# STC32G144K246 register map
Vendor: STC; File version: 2.0
Registers are 8-bit, read-write, no defined reset value unless marked. A register's access mark holds for its fields unless they carry their own. Offsets are from the block's base; [hi:lo] are bit positions.

## PGA2 — 可编程增益放大器 / 运放 2
Base 0x007EF604
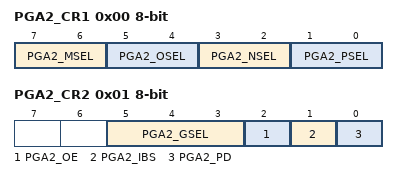
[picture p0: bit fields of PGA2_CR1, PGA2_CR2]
0x00 PGA2_CR1 — 运放2控制寄存器1
  [7:6] PGA2_MSEL — PGA2工作模式选择寄存器
    0=通用运放模式; 1=缓冲模式; 2=反相放大模式; 3=非反相放大模式
  [5:4] PGA2_OSEL — PGA2输出端口选择寄存器
    0=P4.2; 1=P0.0; 2=P7.4; 3=P6.2
  [3:2] PGA2_NSEL — PGA2负极端口选择寄存器
    0=P2.7; 1=P6.1; 2=P7.6; 3=DAC2O
  [1:0] PGA2_PSEL — PGA2正极端口选择寄存器
    0=P2.6; 1=P6.0; 2=P7.5; 3=P7.7
0x01 PGA2_CR2 — 运放2控制寄存器2
  [5:3] PGA2_GSEL — PGA2增益控制寄存器
    0=反相放大增益倍数：N/A；非反相放大增益倍数：N/A; 1=反相放大增益倍数：1；非反相放大增益倍数：2; 2=反相放大增益倍数：2；非反相放大增益倍数：3; 3=反相放大增益倍数：4；非反相放大增益倍数：5; 4=反相放大增益倍数：8；非反相放大增益倍数：9; 5=反相放大增益倍数：16；非反相放大增益倍数：17; 6=反相放大增益倍数：32；非反相放大增益倍数：33; 7=反相放大增益倍数：48；非反相放大增益倍数：49
  [2] PGA2_OE — PGA2 输出控制位
    0=禁止PGA2 输出; 1=允许PGA2 输出
  [1] PGA2_IBS — PGA2 偏压电流大小选择
    0=正常电流大小; 1=电流倍增
  [0] PGA2_PD — PGA2 电源控制
    0=禁止掉电（使能PGA2）; 1=使能掉电（关闭PGA2）

## Comparator3 — 比较器 3 配置与输出状态
Base 0x007EFB78
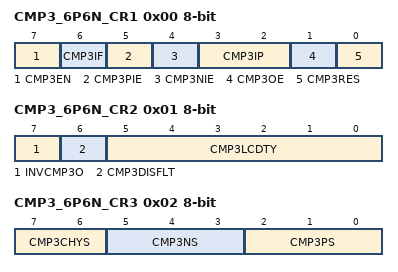
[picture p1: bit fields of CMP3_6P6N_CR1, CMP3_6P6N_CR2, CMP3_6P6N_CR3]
0x00 CMP3_6P6N_CR1 ro — 比较器3控制寄存器1
  [7] CMP3EN — 比较器模块使能位
    0=关闭比较功能; 1=使能比较功能
  [6] CMP3IF — 比较器3 中断标志位。当CMP3PIE 或CMP3NIE 被使能后，若产生相应的中断信号，硬件自 动将CMP3IF 置1，并向CPU 提出中断请求。此标志位必须用户软件向此位写0 清零。
  [5] CMP3PIE — 比较器3 上升沿中断使能位。
    0=禁止比较器3 上升沿中断。; 1=使能比较器3 上升沿中断。使能比较器3 的比较结果由0 变成1 时产生中断请求。
  [4] CMP3NIE — 比较器3 下降沿中断使能位。
    0=禁止比较器3 下降沿中断。; 1=使能比较器3 下降沿中断。使能比较器3 的比较结果由1 变成0 时产生中断请求。
  [3:2] CMP3IP — 比较器3 中断优先级设置。
    0=比较器3 中断为最低优先级。; 1=比较器3 中断为较低优先级。; 2=比较器3 中断为较高优先级。; 3=比较器3 中断为最高优先级。
  [1] CMP3OE — 比较器结果输出控制位
    0=禁止比较器结果输出; 1=使能比较器结果输出。
  [0] CMP3RES — 比较器的比较结果。此位为只读。
    0=表示CMP3+的电平低于CMP3-的电平; 1=表示CMP3+的电平高于CMP3-的电平
0x01 CMP3_6P6N_CR2 ro — 比较器3控制寄存器2
  [7] INVCMP3O — 比较器结果输出控制
    0=比较器结果正向输出。若CMP3RES 为0，则输出低电平，反之输出高电平。; 1=比较器结果反向输出。若CMP3RES 为0，则输出高电平，反之输出低电平。
  [6] CMP3DISFLT — 模拟滤波功能控制
    0=使能0.1us 模拟滤波功能; 1=关闭0.1us 模拟滤波功能，可略微提高比较器的比较速度。
  [5:0] CMP3LCDTY — 数字滤波功能控制 数字滤波功能即为数字信号去抖动功能。当比较结果发生上升沿或者下降沿变化时，比较器侦测变 化后的信号必须维持LCDTY 所设置的CPU 时钟数不发生变化，才认为数据变化是有效的；否 则将视同信号无变化。 注意：当使能数字滤波功能后，芯片内部实际的等待时钟需额外增加两个状态机切换时间，
0x02 CMP3_6P6N_CR3 ro — 比较器3控制寄存器3
  [7:6] CMP3CHYS — 比较器DC 迟滞输入选择
  [5:3] CMP3NS — 比较器负端输入选择
    0=P7.6; 1=P5.2; 2=OP4O; 3=1.19V; 4=DAC1O; 5=DAC2O
  [2:0] CMP3PS — 比较器正端输入选择
    0=P7.7; 1=P5.3; 2=OP3O; 3=ADC2IN; 4=DAC1O; 5=DAC2O
0x03 CMP3_6P6N_CR4 ro — 比较器3控制寄存器4
  [1:0] CMP3O_S — 比较器输出端口选择
    0=P2.4; 1=P4.5; 2=Value_2; 3=Value_3

## PGA3 — 可编程增益放大器 / 运放 3
Base 0x007EF608
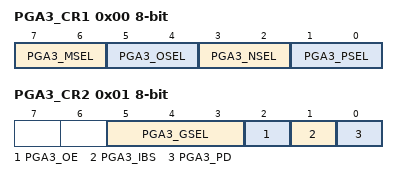
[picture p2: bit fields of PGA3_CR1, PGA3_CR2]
0x00 PGA3_CR1 — 运放3控制寄存器1
  [7:6] PGA3_MSEL — PGA3工作模式选择寄存器
    0=通用运放模式; 1=缓冲模式; 2=反相放大模式; 3=非反相放大模式
  [5:4] PGA3_OSEL — PGA3输出端口选择寄存器
    0=P3.2; 1=P2.1; 2=P7.4; 3=P5.0
  [3:2] PGA3_NSEL — PGA3负极端口选择寄存器
    0=P5.1; 1=P4.2; 2=P7.1; 3=DAC2O
  [1:0] PGA3_PSEL — PGA3正极端口选择寄存器
    0=P3.5; 1=P2.0; 2=P7.0; 3=DAC2O
0x01 PGA3_CR2 — 运放3控制寄存器2
  [5:3] PGA3_GSEL — PGA3增益控制寄存器
    0=反相放大增益倍数：N/A；非反相放大增益倍数：N/A; 1=反相放大增益倍数：1；非反相放大增益倍数：2; 2=反相放大增益倍数：2；非反相放大增益倍数：3; 3=反相放大增益倍数：4；非反相放大增益倍数：5; 4=反相放大增益倍数：8；非反相放大增益倍数：9; 5=反相放大增益倍数：16；非反相放大增益倍数：17; 6=反相放大增益倍数：32；非反相放大增益倍数：33; 7=反相放大增益倍数：48；非反相放大增益倍数：49
  [2] PGA3_OE — PGA3 输出控制位
    0=禁止PGA3 输出; 1=允许PGA3 输出
  [1] PGA3_IBS — PGA3 偏压电流大小选择
    0=正常电流大小; 1=电流倍增
  [0] PGA3_PD — PGA3 电源控制
    0=禁止掉电（使能PGA3）; 1=使能掉电（关闭PGA3）

## Comparator4 — 比较器 4 配置与输出状态
Base 0x007EFB7C
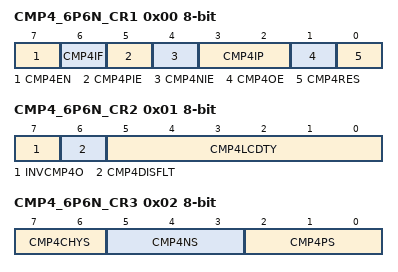
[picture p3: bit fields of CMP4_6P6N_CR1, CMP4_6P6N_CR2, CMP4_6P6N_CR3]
0x00 CMP4_6P6N_CR1 ro — 比较器4控制寄存器1
  [7] CMP4EN — 比较器模块使能位
    0=关闭比较功能; 1=使能比较功能
  [6] CMP4IF — 比较器4 中断标志位。当CMP4PIE 或CMP4NIE 被使能后，若产生相应的中断信号，硬件自 动将CMP4IF 置1，并向CPU 提出中断请求。此标志位必须用户软件向此位写0 清零。
  [5] CMP4PIE — 比较器4 上升沿中断使能位。
    0=禁止比较器4 上升沿中断。; 1=使能比较器4 上升沿中断。使能比较器4 的比较结果由0 变成1 时产生中断请求。
  [4] CMP4NIE — 比较器4 下降沿中断使能位。
    0=禁止比较器4 下降沿中断。; 1=使能比较器4 下降沿中断。使能比较器4 的比较结果由1 变成0 时产生中断请求。
  [3:2] CMP4IP — 比较器4 中断优先级设置。
    0=比较器4 中断为最低优先级。; 1=比较器4 中断为较低优先级。; 2=比较器4 中断为较高优先级。; 3=比较器4 中断为最高优先级。
  [1] CMP4OE — 比较器结果输出控制位
    0=禁止比较器结果输出; 1=使能比较器结果输出。
  [0] CMP4RES — 比较器的比较结果。此位为只读。
    0=表示CMP4+的电平低于CMP4-的电平; 1=表示CMP4+的电平高于CMP4-的电平
0x01 CMP4_6P6N_CR2 ro — 比较器4控制寄存器2
  [7] INVCMP4O — 比较器结果输出控制
    0=比较器结果正向输出。若CMP4RES 为0，则输出低电平，反之输出高电平。; 1=比较器结果反向输出。若CMP4RES 为0，则输出高电平，反之输出低电平。
  [6] CMP4DISFLT — 模拟滤波功能控制
    0=使能0.1us 模拟滤波功能; 1=关闭0.1us 模拟滤波功能，可略微提高比较器的比较速度。
  [5:0] CMP4LCDTY — 数字滤波功能控制 数字滤波功能即为数字信号去抖动功能。当比较结果发生上升沿或者下降沿变化时，比较器侦测变 化后的信号必须维持LCDTY 所设置的CPU 时钟数不发生变化，才认为数据变化是有效的；否 则将视同信号无变化。 注意：当使能数字滤波功能后，芯片内部实际的等待时钟需额外增加两个状态机切换时间，
0x02 CMP4_6P6N_CR3 ro — 比较器4控制寄存器3
  [7:6] CMP4CHYS — 比较器DC 迟滞输入选择
  [5:3] CMP4NS — 比较器负端输入选择
    0=P2.6; 1=P4.4; 2=OP1O; 3=1.19V; 4=DAC1O; 5=DAC2O
  [2:0] CMP4PS — 比较器正端输入选择
    0=P2.7; 1=P4.3; 2=OP4O; 3=ADC2IN; 4=DAC1O; 5=DAC2O
0x03 CMP4_6P6N_CR4 ro — 比较器4控制寄存器4
  [1:0] CMP4O_S — 比较器输出端口选择
    0=P2.5; 1=P4.6; 2=Value_2; 3=Value_3
